# PIC32MZ2051W104132 register map
Vendor: Microchip
Registers are 32-bit, read-write, no defined reset value unless marked. A register's access mark holds for its fields unless they carry their own. Addresses are absolute, and some are shared; only a register's first bit layout is shown; [hi:lo] are bit positions; {n}, {i} and the like mark numbered series.

## PORTC
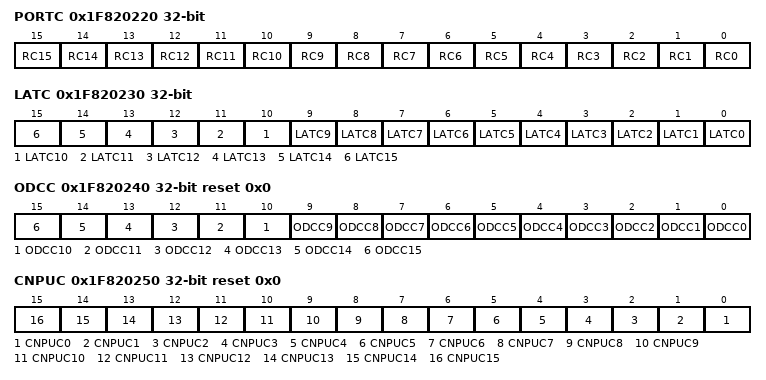
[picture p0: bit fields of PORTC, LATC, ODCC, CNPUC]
0x1F820220 PORTC — (power-on value ----------------xxxxxxxxxxxxxxxx)
  [n] RC{n} (n=0..15)
0x1F820230 LATC — (power-on value ----------------xxxxxxxxxxxxxxxx)
  [n] LATC{n} (n=0..15)
0x1F820240 ODCC reset 0x0
  [n] ODCC{n} (n=0..15)
0x1F820250 CNPUC reset 0x0
  [n] CNPUC{n} (n=0..15)
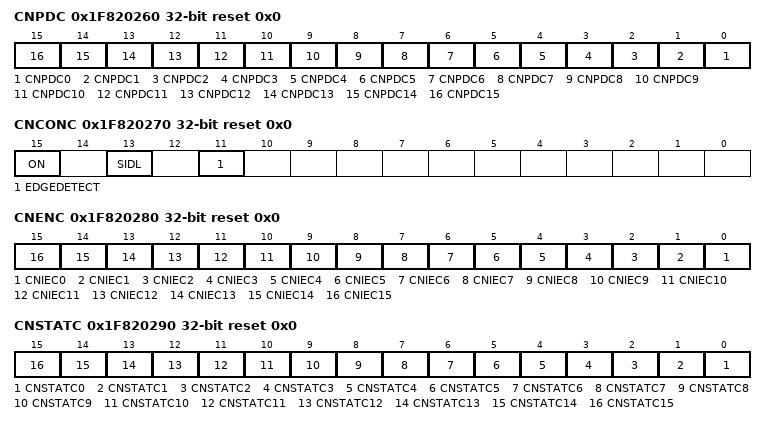
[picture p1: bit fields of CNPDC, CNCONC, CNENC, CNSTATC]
0x1F820260 CNPDC reset 0x0
  [n] CNPDC{n} (n=0..15)
0x1F820270 CNCONC reset 0x0
  [15] ON, [13] SIDL, [11] EDGEDETECT
0x1F820280 CNENC reset 0x0
  [n] CNIEC{n} (n=0..15)
0x1F820290 CNSTATC reset 0x0
  [n] CNSTATC{n} (n=0..15)
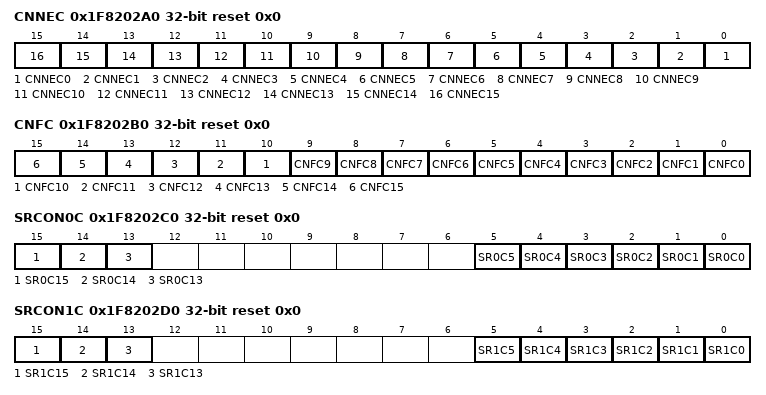
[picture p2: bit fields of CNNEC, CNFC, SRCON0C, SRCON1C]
0x1F8202A0 CNNEC reset 0x0
  [n] CNNEC{n} (n=0..15)
0x1F8202B0 CNFC reset 0x0
  [n] CNFC{n} (n=0..15)
0x1F8202C0 SRCON0C reset 0x0
  [15] SR0C15, [14] SR0C14, [13] SR0C13, [n] SR0C{n} (n=0..5)
0x1F8202D0 SRCON1C reset 0x0
  [15] SR1C15, [14] SR1C14, [13] SR1C13, [n] SR1C{n} (n=0..5)

## PORTK
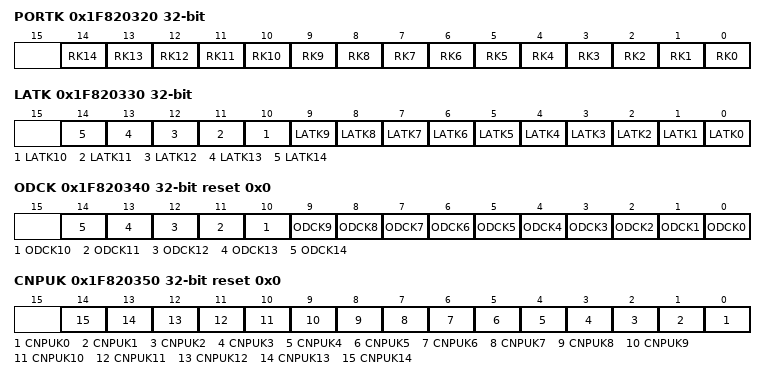
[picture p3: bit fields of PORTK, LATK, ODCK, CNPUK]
0x1F820320 PORTK — (power-on value -----------------xxxxxxxxxxxxxxx)
  [n] RK{n} (n=0..14)
0x1F820330 LATK — (power-on value -----------------xxxxxxxxxxxxxxx)
  [n] LATK{n} (n=0..14)
0x1F820340 ODCK reset 0x0
  [n] ODCK{n} (n=0..14)
0x1F820350 CNPUK reset 0x0
  [n] CNPUK{n} (n=0..14)
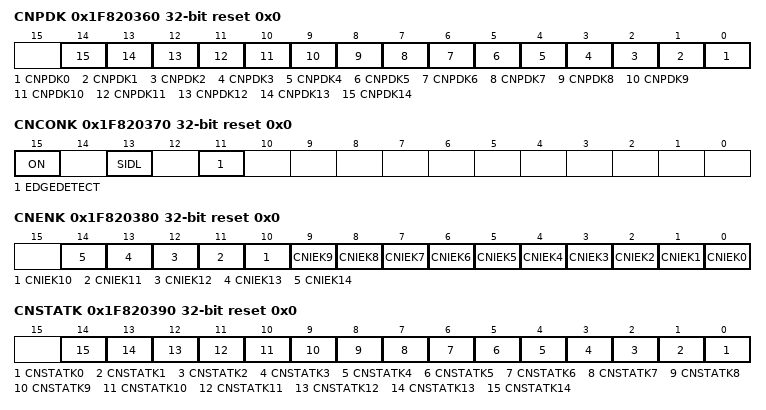
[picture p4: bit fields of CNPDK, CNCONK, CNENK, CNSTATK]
0x1F820360 CNPDK reset 0x0
  [n] CNPDK{n} (n=0..14)
0x1F820370 CNCONK reset 0x0
  [15] ON, [13] SIDL, [11] EDGEDETECT
0x1F820380 CNENK reset 0x0
  [n] CNIEK{n} (n=0..14)
0x1F820390 CNSTATK reset 0x0
  [n] CNSTATK{n} (n=0..14)
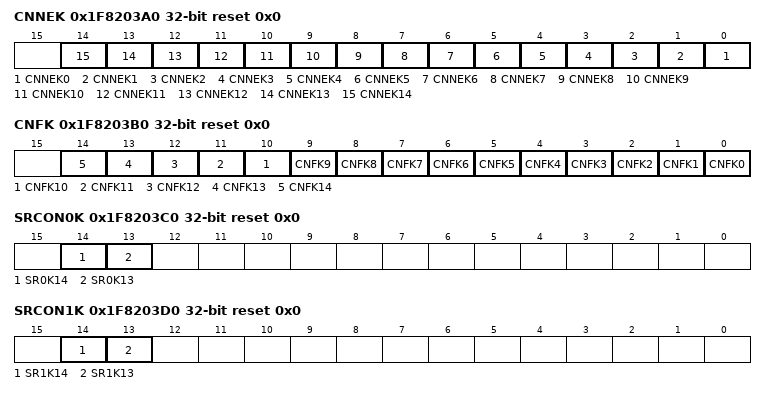
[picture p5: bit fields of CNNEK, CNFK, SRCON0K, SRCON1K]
0x1F8203A0 CNNEK reset 0x0
  [n] CNNEK{n} (n=0..14)
0x1F8203B0 CNFK reset 0x0
  [n] CNFK{n} (n=0..14)
0x1F8203C0 SRCON0K reset 0x0
  [14] SR0K14, [13] SR0K13
0x1F8203D0 SRCON1K reset 0x0
  [14] SR1K14, [13] SR1K13

## I2C1
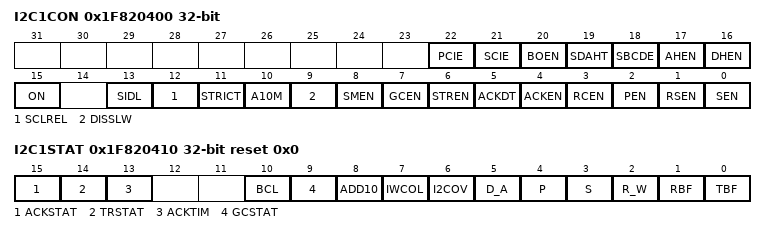
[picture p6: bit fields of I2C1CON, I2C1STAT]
0x1F820400 I2C1CON — (power-on value ---------00000000x01000000000000)
  [22] PCIE, [21] SCIE, [20] BOEN, [19] SDAHT, [18] SBCDE, [17] AHEN, [16] DHEN, [15] ON, [13] SIDL, [12] SCLREL, [11] STRICT, [10] A10M, [9] DISSLW, [8] SMEN, [7] GCEN, [6] STREN, [5] ACKDT, [4] ACKEN, [3] RCEN, [2] PEN, [1] RSEN, [0] SEN
0x1F820410 I2C1STAT reset 0x0
  [15] ACKSTAT ro
  [14] TRSTAT ro
  [13] ACKTIM ro
  [10] BCL — (can only be cleared)
  [9] GCSTAT ro
  [8] ADD10 ro
  [7] IWCOL — (can only be cleared)
  [6] I2COV — (can only be cleared)
  [5] D_A ro
  [4] P — (can only be cleared)
  [3] S — (can only be cleared)
  [2] R_W ro
  [1] RBF ro
  [0] TBF ro
0x1F820420 I2C1ADD reset 0x0
  [9:0] I2CADD
0x1F820430 I2C1MSK reset 0x0
  [9:0] I2CMSK
0x1F820440 I2C1BRG reset 0x0
  [15:0] I2CBRG
0x1F820450 I2C1TRN wo reset 0xFF
  [7:0] I2CTRN
0x1F820460 I2C1RCV ro reset 0x0
  [7:0] I2CRCV

## ADCHS1
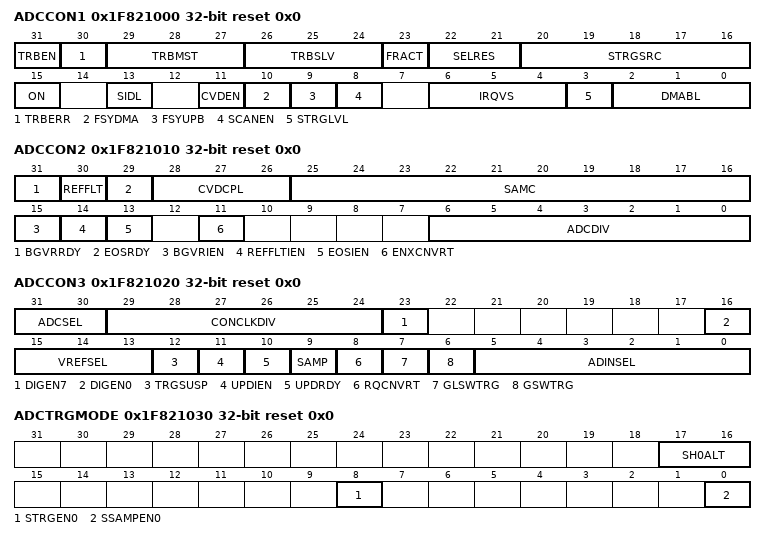
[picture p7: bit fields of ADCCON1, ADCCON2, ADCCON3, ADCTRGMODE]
0x1F821000 ADCCON1 reset 0x0
  [31] TRBEN, [30] TRBERR ro, [29:27] TRBMST, [26:24] TRBSLV, [23] FRACT, [22:21] SELRES, [20:16] STRGSRC, [15] ON, [13] SIDL, [11] CVDEN, [10] FSYDMA, [9] FSYUPB, [8] SCANEN, [6:4] IRQVS, [3] STRGLVL, [2:0] DMABL
0x1F821010 ADCCON2 reset 0x0
  [31] BGVRRDY ro, [30] REFFLT ro, [29] EOSRDY ro, [28:26] CVDCPL, [25:16] SAMC, [15] BGVRIEN, [14] REFFLTIEN, [13] EOSIEN, [11] ENXCNVRT, [6:0] ADCDIV
0x1F821020 ADCCON3 reset 0x0
  [31:30] ADCSEL, [29:24] CONCLKDIV, [23] DIGEN7 ro, [16] DIGEN0 ro, [15:13] VREFSEL, [12] TRGSUSP, [11] UPDIEN, [10] UPDRDY, [9] SAMP, [8] RQCNVRT, [7] GLSWTRG, [6] GSWTRG, [5:0] ADINSEL
0x1F821030 ADCTRGMODE reset 0x0
  [17:16] SH0ALT, [8] STRGEN0, [0] SSAMPEN0
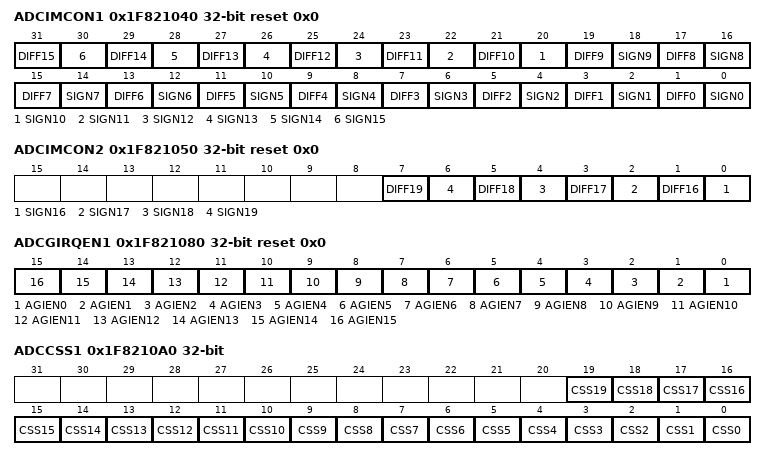
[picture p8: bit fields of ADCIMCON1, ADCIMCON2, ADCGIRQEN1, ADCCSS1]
0x1F821040 ADCIMCON1 reset 0x0
  [2n+1] DIFF{n} (n=0..15), [2n] SIGN{n} (n=0..15)
0x1F821050 ADCIMCON2 reset 0x0
  [2n-31] DIFF{n} (n=16..19), [2n-32] SIGN{n} (n=16..19)
0x1F821080 ADCGIRQEN1 reset 0x0
  [n] AGIEN{n} (n=0..15)
0x1F8210A0 ADCCSS1 — (power-on value ------------xxxx0000000000000000)
  [n] CSS{n} (n=0..19)
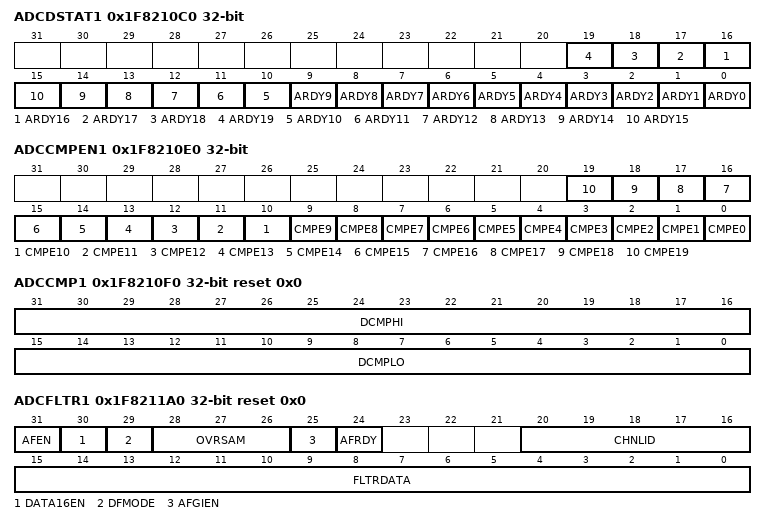
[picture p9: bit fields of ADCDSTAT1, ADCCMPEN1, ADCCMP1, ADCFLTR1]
0x1F8210C0 ADCDSTAT1 — (power-on value ------------xxxx0000000000000000)
  [n] ARDY{n} (n=16..19), [n] ARDY{n} ro (n=0..15)
0x1F8210E0 ADCCMPEN1 — (power-on value ------------xxxx0000000000000000)
  [n] CMPE{n} (n=0..19)
0x1F8210F0 ADCCMP1 reset 0x0
  [31:16] DCMPHI, [15:0] DCMPLO
0x1F8211A0 ADCFLTR1 reset 0x0
  [31] AFEN, [30] DATA16EN, [29] DFMODE, [28:26] OVRSAM, [25] AFGIEN, [24] AFRDY ro, [20:16] CHNLID, [15:0] FLTRDATA ro
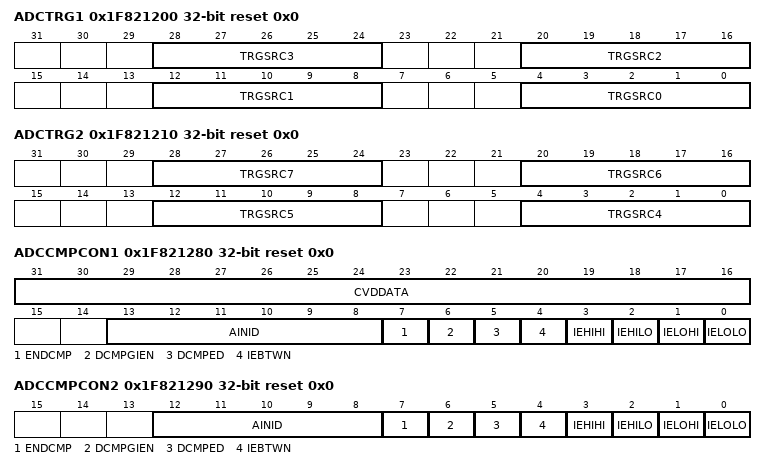
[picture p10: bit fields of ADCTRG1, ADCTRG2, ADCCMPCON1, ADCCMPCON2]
0x1F821200 ADCTRG1 reset 0x0
  [8n+4:8n] TRGSRC{n} (n=0..3)
0x1F821210 ADCTRG2 reset 0x0
  [8n-28:8n-32] TRGSRC{n} (n=4..7)
0x1F821280 ADCCMPCON1 reset 0x0
  [31:16] CVDDATA ro, [13:8] AINID ro, [7] ENDCMP, [6] DCMPGIEN, [5] DCMPED ro, [4] IEBTWN, [3] IEHIHI, [2] IEHILO, [1] IELOHI, [0] IELOLO
0x1F821290 ADCCMPCON2 reset 0x0
  [12:8] AINID ro, [7] ENDCMP, [6] DCMPGIEN, [5] DCMPED ro, [4] IEBTWN, [3] IEHIHI, [2] IEHILO, [1] IELOHI, [0] IELOLO
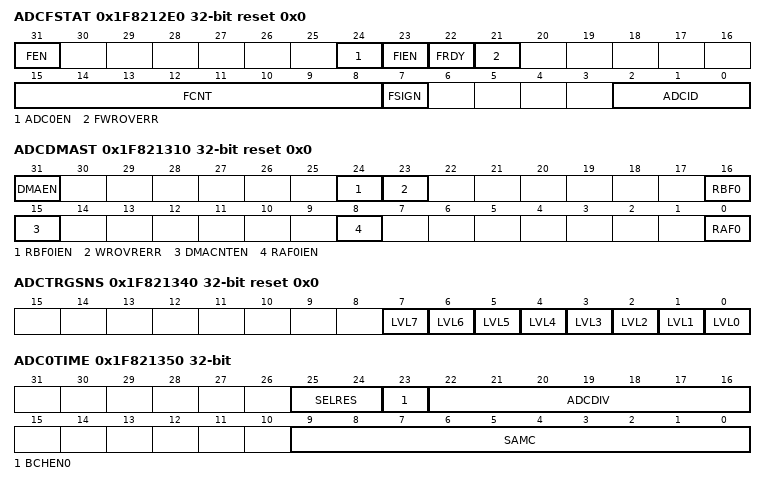
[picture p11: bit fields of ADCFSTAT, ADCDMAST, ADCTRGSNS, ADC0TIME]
0x1F8212E0 ADCFSTAT reset 0x0
  [31] FEN, [24] ADC0EN, [23] FIEN, [22] FRDY ro, [21] FWROVERR ro, [15:8] FCNT ro, [7] FSIGN ro, [2:0] ADCID
0x1F8212F0 ADCFIFO ro reset 0x0
  [31:0] DATA
0x1F821300 ADCBASE reset 0x0
  [15:0] ADCBASE
0x1F821310 ADCDMAST reset 0x0
  [31] DMAEN, [24] RBF0IEN, [23] WROVRERR ro, [16] RBF0 ro, [15] DMACNTEN, [8] RAF0IEN, [0] RAF0 ro
0x1F821320 ADCCNTB reset 0x0
0x1F821330 ADCDMAB reset 0x0
  [31:0] ADDMAB
0x1F821340 ADCTRGSNS reset 0x0
  [n] LVL{n} (n=0..7)
0x1F821350 ADC0TIME — (power-on value ------00x0000000------0000000000)
  [25:24] SELRES, [23] BCHEN0, [22:16] ADCDIV, [9:0] SAMC
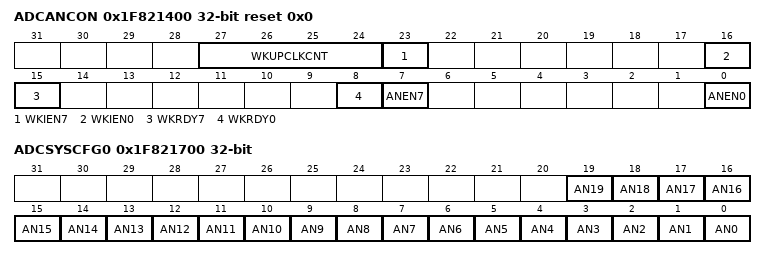
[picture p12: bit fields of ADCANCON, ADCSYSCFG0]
0x1F821400 ADCANCON reset 0x0
  [27:24] WKUPCLKCNT, [23] WKIEN7, [16] WKIEN0, [15] WKRDY7 ro, [8] WKRDY0 ro, [7] ANEN7, [0] ANEN0
0x1F821600 ADC0CFG reset 0x0
  [31:0] ADCCFG
0x1F821670 ADC7CFG reset 0x0
  [31:0] ADCCFG
0x1F821700 ADCSYSCFG0 — (power-on value ------------xxxx0000000000000000)
  [n] AN{n} (n=16..19), [n] AN{n} ro (n=0..15)
{0x1F821A00+0x10*i} ADCDATA{i} reset 0x0 (i=0..23)
  [31:0] DATA
